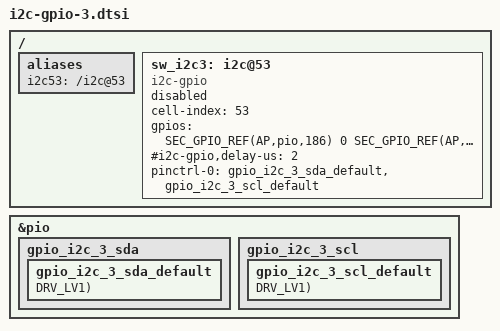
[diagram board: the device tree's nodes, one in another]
&pio {
       gpio_i2c_3_sda {
               gpio_i2c_3_sda_default: gpio_i2c_3_sda_default {
                       GPIO_CONFIG_PUD_DRV(AP,pio,186, FUNC_INPUT, PULL_NONE, DRV_LV1);
               };
       };
};

&pio {
       gpio_i2c_3_scl {
               gpio_i2c_3_scl_default: gpio_i2c_3_scl_default {
                       GPIO_CONFIG_PUD_DRV(AP,pio,185, FUNC_INPUT, PULL_NONE, DRV_LV1);
               };
       };
};

/ {
	fragment@model {
		target-path = "/";
	        __overlay__ {
			aliases {
				  i2c53 = "/i2c@53";
			};
			/* Software I2C */
			sw_i2c3: i2c@53 {
				cell-index = <53>;
				compatible = "i2c-gpio";
				gpios = <
					SEC_GPIO_REF(AP,pio,186) 0 /* SDA */
					SEC_GPIO_REF(AP,pio,185) 0 /* SCL */
					>;
				#i2c-gpio,delay-us = <2>;
				#address-cells = <1>;
				#size-cells = <0>;

				pinctrl-names = "default";
				pinctrl-0 = <
					&gpio_i2c_3_sda_default
					&gpio_i2c_3_scl_default
					>;

				status = "disabled";
			};
		};
	};
};

